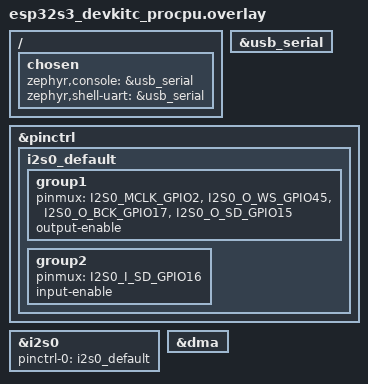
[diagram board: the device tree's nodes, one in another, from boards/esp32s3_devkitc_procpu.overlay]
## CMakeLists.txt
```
cmake_minimum_required(VERSION 3.20.0)
find_package(Zephyr REQUIRED HINTS $ENV{ZEPHYR_BASE})
project(i2s_test)
target_sources(app PRIVATE src/main.c)
```

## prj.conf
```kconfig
# Console
CONFIG_PRINTK=y
CONFIG_CONSOLE=y
CONFIG_UART_CONSOLE=y
CONFIG_SERIAL=y

# I2S
CONFIG_I2S=y

# DMA (required for ESP32-S3 I2S)
CONFIG_DMA=y

# Stack
CONFIG_MAIN_STACK_SIZE=4096

# Logging
CONFIG_LOG=y
```

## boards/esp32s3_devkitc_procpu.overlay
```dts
/* CHD-ESP32-S3-BOX: I2S0 Basic Test */
/* MCLK=IO2, BCLK=IO17, WS=IO45, DOUT=IO15, DIN=IO16 */

#include <zephyr/dt-bindings/pinctrl/esp-pinctrl-common.h>
#include <dt-bindings/pinctrl/esp32s3-pinctrl.h>
#include <zephyr/dt-bindings/pinctrl/esp32s3-gpio-sigmap.h>

/ {
	chosen {
		zephyr,console = &usb_serial;
		zephyr,shell-uart = &usb_serial;
	};
};

&usb_serial {
	status = "okay";
};

&pinctrl {
	i2s0_default: i2s0_default {
		group1 {
			pinmux = <I2S0_MCLK_GPIO2>,
				 <I2S0_O_WS_GPIO45>,
				 <I2S0_O_BCK_GPIO17>,
				 <I2S0_O_SD_GPIO15>;
			output-enable;
		};
		group2 {
			pinmux = <I2S0_I_SD_GPIO16>;
			input-enable;
		};
	};
};

i2s_rxtx: &i2s0 {
	pinctrl-0 = <&i2s0_default>;
	pinctrl-names = "default";
	status = "okay";
};

&dma {
	status = "okay";
};
```

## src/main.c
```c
/*
 * CHD-ESP32-S3-BOX: I2S Basic Test
 * Step 6.1 — I2S peripheral init + sine wave TX
 *
 * Outputs a 1kHz sine wave through I2S0 TX.
 * Without ES8311 codec configured, no audible sound,
 * but verifies I2S peripheral and DMA work correctly.
 */

#include <zephyr/kernel.h>
#include <zephyr/device.h>
#include <zephyr/drivers/i2s.h>
#include <string.h>
#include <math.h>

#define I2S_TX_NODE     DT_NODELABEL(i2s_rxtx)

#define SAMPLE_RATE     16000
#define SAMPLE_BITS     16
#define NUM_CHANNELS    2
#define BYTES_PER_SAMPLE sizeof(int16_t)

/* 10ms worth of samples per block */
#define SAMPLES_PER_BLOCK ((SAMPLE_RATE / 100) * NUM_CHANNELS)
#define BLOCK_SIZE        (SAMPLES_PER_BLOCK * BYTES_PER_SAMPLE)
#define BLOCK_COUNT       6

K_MEM_SLAB_DEFINE_STATIC(tx_mem_slab, BLOCK_SIZE, BLOCK_COUNT, 4);

/* Pre-computed 1kHz sine wave table (one period at 16kHz = 16 samples) */
#define SINE_TABLE_LEN 16
static const int16_t sine_table[SINE_TABLE_LEN] = {
	0, 12539, 23170, 30273, 32767, 30273, 23170, 12539,
	0, -12539, -23170, -30273, -32767, -30273, -23170, -12539
};

static void fill_sine_block(int16_t *buf, int num_samples, int *phase)
{
	for (int i = 0; i < num_samples; i += NUM_CHANNELS) {
		int16_t val = sine_table[*phase % SINE_TABLE_LEN];
		buf[i] = val;         /* Left channel */
		buf[i + 1] = val;    /* Right channel */
		(*phase)++;
		if (*phase >= SINE_TABLE_LEN) {
			*phase = 0;
		}
	}
}

int main(void)
{
	const struct device *i2s_dev = DEVICE_DT_GET(I2S_TX_NODE);
	struct i2s_config config;
	int ret;
	int phase = 0;

	printk("=== I2S Basic Test ===\n");

	if (!device_is_ready(i2s_dev)) {
		printk("ERROR: I2S device not ready\n");
		return 0;
	}
	printk("I2S device: %s\n", i2s_dev->name);

	/* Configure I2S TX */
	config.word_size = SAMPLE_BITS;
	config.channels = NUM_CHANNELS;
	config.format = I2S_FMT_DATA_FORMAT_I2S;
	config.options = I2S_OPT_BIT_CLK_MASTER | I2S_OPT_FRAME_CLK_MASTER;
	config.frame_clk_freq = SAMPLE_RATE;
	config.mem_slab = &tx_mem_slab;
	config.block_size = BLOCK_SIZE;
	config.timeout = 1000;

	ret = i2s_configure(i2s_dev, I2S_DIR_TX, &config);
	if (ret < 0) {
		printk("ERROR: I2S TX configure failed: %d\n", ret);
		return 0;
	}
	printk("I2S TX configured: %dHz, %d-bit, %d-ch\n",
	       SAMPLE_RATE, SAMPLE_BITS, NUM_CHANNELS);

	/* Pre-fill 2 blocks before starting */
	for (int i = 0; i < 2; i++) {
		void *mem_block;
		ret = k_mem_slab_alloc(&tx_mem_slab, &mem_block, K_NO_WAIT);
		if (ret < 0) {
			printk("ERROR: Block alloc failed: %d\n", ret);
			return 0;
		}
		fill_sine_block(mem_block, SAMPLES_PER_BLOCK, &phase);
		ret = i2s_write(i2s_dev, mem_block, BLOCK_SIZE);
		if (ret < 0) {
			printk("ERROR: I2S write failed: %d\n", ret);
			return 0;
		}
	}

	/* Start TX stream */
	ret = i2s_trigger(i2s_dev, I2S_DIR_TX, I2S_TRIGGER_START);
	if (ret < 0) {
		printk("ERROR: I2S TX start failed: %d\n", ret);
		return 0;
	}
	printk("I2S TX started — streaming 1kHz sine wave\n");

	/* Continuously feed blocks */
	uint32_t blocks_sent = 2;
	while (1) {
		void *mem_block;
		ret = k_mem_slab_alloc(&tx_mem_slab, &mem_block, K_MSEC(500));
		if (ret < 0) {
			printk("WARN: Block alloc timeout\n");
			continue;
		}
		fill_sine_block(mem_block, SAMPLES_PER_BLOCK, &phase);
		ret = i2s_write(i2s_dev, mem_block, BLOCK_SIZE);
		if (ret < 0) {
			printk("ERROR: I2S write failed: %d\n", ret);
			k_mem_slab_free(&tx_mem_slab, mem_block);
			break;
		}
		blocks_sent++;
		if ((blocks_sent % 1000) == 0) {
			printk("I2S TX blocks sent: %u\n", blocks_sent);
		}
	}

	return 0;
}
```
